# CC2756 register map
File version: 1.0
CPU: CM4 r0p4, little endian, no MPU, no FPU, VTOR, 3 interrupt priority bits
Registers are 32-bit, read-write, reset 0x0 unless marked. A register's access mark holds for its fields unless they carry their own. Offsets are from the block's base; [hi:lo] are bit positions.

## SAU
Base 0xE000EDD0
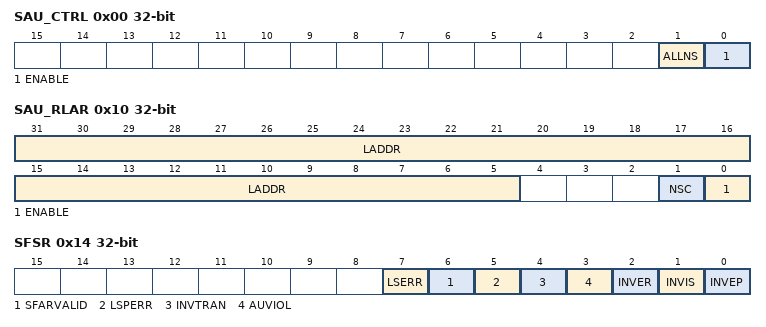
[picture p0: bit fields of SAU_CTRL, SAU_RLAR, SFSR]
0x00 SAU_CTRL — Allows enabling of the Security Attribution Unit
  [1] ALLNS — When SAU_CTRL.ENABLE is 0 this bit controls if the memory is marked as Non-secure or Secure
  [0] ENABLE — Enables the SAU
0x04 SAU_TYPE reset 0x4 — Indicates the number of regions implemented by the Security Attribution Unit
  [7:0] SREGION ro — The number of implemented SAU regions
0x08 SAU_RNR — Selects the region currently accessed by SAU_RBAR and SAU_RLAR
  [7:0] REGION — Indicates the SAU region accessed by SAU_RBAR and SAU_RLAR
0x0C SAU_RBAR — Provides indirect read and write access to the base address of the currently selected SAU region
  [31:5] BADDR — Holds bits [31:5] of the base address for the selected SAU region
0x10 SAU_RLAR — Provides indirect read and write access to the limit address of the currently selected SAU region
  [31:5] LADDR — Holds bits [31:5] of the limit address for the selected SAU region
  [1] NSC — Controls whether Non-secure state is permitted to execute an SG instruction from this region
  [0] ENABLE — SAU region enable
0x14 SFSR — Provides information about any security related faults
  [7] LSERR — Sticky flag indicating that an error occurred during lazy state activation or deactivation
  [6] SFARVALID — This bit is set when the SFAR register contains a valid value. As with similar fields, such as BFSR.BFARVALID and MMFSR.MMARVALID, this bit can be cleared by other exceptions, such as BusFault
  [5] LSPERR — Stick flag indicating that an SAU or IDAU violation occurred during the lazy preservation of floating-point state
  [4] INVTRAN — Sticky flag indicating that an exception was raised due to a branch that was not flagged as being domain crossing causing a transition from Secure to Non-secure memory
  [3] AUVIOL — Sticky flag indicating that an attempt was made to access parts of the address space that are marked as Secure with NS-Req for the transaction set to Non-secure. This bit is not set if the violation occurred during lazy state preservation. See LSPERR
  [2] INVER — This can be caused by EXC_RETURN.DCRS being set to 0 when returning from an exception in the Non-secure state, or by EXC_RETURN.ES being set to 1 when returning from an exception in the Non-secure state
  [1] INVIS — This bit is set if the integrity signature in an exception stack frame is found to be invalid during the unstacking operation
  [0] INVEP — This bit is set if a function call from the Non-secure state or exception targets a non-SG instruction in the Secure state. This bit is also set if the target address is a SG instruction, but there is no matching SAU/IDAU region with the NSC flag set
0x18 SFAR — Shows the address of the memory location that caused a Security violation
  [31:0] ADDRESS — The address of an access that caused a attribution unit violation. This field is only valid when SFSR.SFARVALID is set. This allows the actual flip flops associated with this register to be shared with other fault address registers. If an implementation chooses to share the storage in this way, care must be taken to not leak Secure address information to the Non-secure state. One way of achieving this is to share the SFAR register with the MMFAR_S register, which is not accessible to the Non-secure state

## SRAMCTRL — System SRAM Controller
Base 0x400C5000
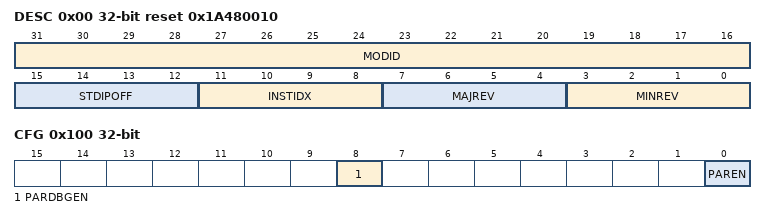
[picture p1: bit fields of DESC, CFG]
0x00 DESC ro reset 0x1A480010 — This register identifies the peripheral
  [31:16] MODID — Module identifier
  [15:12] STDIPOFF — 64 B Standard IP MMR block$lt;br$gt;0: STDIP MMRs do not exist$lt;br$gt;1:15: These MMRs begin at offset 64*STDIPOFF from IP base address
  [11:8] INSTIDX — IP Instance number
  [7:4] MAJREV — Major revision
  [3:0] MINREV — Minor revision
0x64 DTB — This bit field is used to select DTB mux digital inputs
  [1:0] SEL — DTB Selection
0x100 CFG — Configuration Register
  [8] PARDBGEN — SRAM Parity Debug Enable.
    1=EN (Enable Parity Debug. An address offset can be written to PARDBG.ADDR and parity errors will be generated on reads from within this offset); 0=DIS (Disable Parity Debug. Normal operation)
  [0] PAREN — SRAM Parity Enable.
    1=EN (Enable Parity); 0=DIS (Disable Parity)
0x104 INITSEL — Initilizataion Select Register.
  [6:0] SEL — Bank Select. Bit[0]:Bank-0 Bit[1]:Bank-1 ... Bit[n]:Bank-n
0x108 INITTRIG — Initilizataion Select Register. This register is writable only if CFG.LOCKDIS = 1
  [0] TRG — Trigger Initilization. All banks with its INIT.SEL[x] bit set to 1 will be initilizaed. This bit will auto clear once initlization is complete
0x10C INITSTAT ro — Initilizataion Status
  [6:0] BUSY — Each bit indicate that corresponding bank is getting initialzed
0x110 PARDBG — Parity error check debug address setting
  [19:2] ADDR — Debug Parity Error Address Offset.##br##When CFG.PARDBGEN is 1, this field is used to set a parity debug address offset. Writes within this address offset will force incorrect parity bits to be stored together with the data written. The following reads within this same address offset will thus result in parity errors to be generated.
0x114 PARERR ro — Parity error
  [31:0] ADDR — Parity Error Address Offset.##br##This holds the address offset that first generated the parity error and an interrupt is generated. ##br##This register is 'Clear-On-Read'

## SYSTICK
Base 0xE000E010
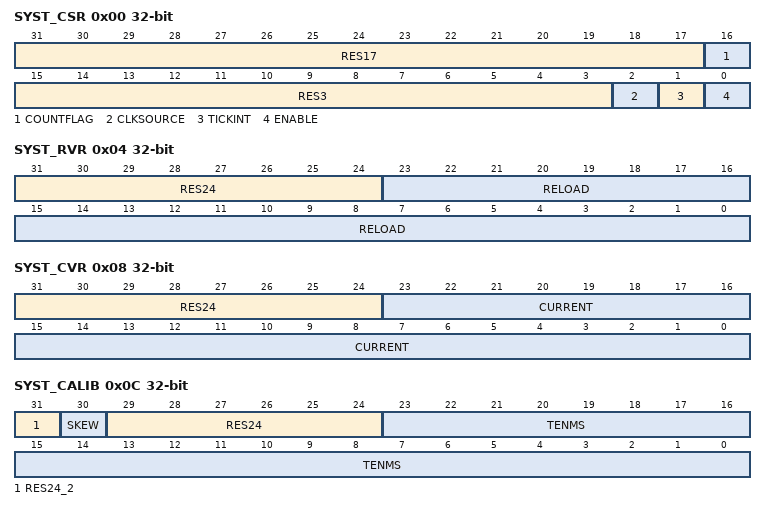
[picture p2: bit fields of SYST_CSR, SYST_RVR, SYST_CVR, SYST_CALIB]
0x00 SYST_CSR — Controls and provides status date for the SysTick timer
  [31:17] RES17 ro — Software should not rely on the value of a reserved. Writing any other value than the reset value may result in undefined behavior.
  [16] COUNTFLAG — Indicates whether the counter has counted to zero since the last read of this register
  [15:3] RES3 ro — Software should not rely on the value of a reserved. Writing any other value than the reset value may result in undefined behavior.
  [2] CLKSOURCE — Indicates the SysTick clock source
  [1] TICKINT — Indicates whether counting to 0 causes the status of the SysTick exception to change to pending
  [0] ENABLE — Indicates the enabled status of the SysTick counter
0x04 SYST_RVR — Specifies the SysTick timer counter reload value
  [31:24] RES24 ro — Software should not rely on the value of a reserved. Writing any other value than the reset value may result in undefined behavior.
  [23:0] RELOAD — Value to load into the SYST_CVR when the counter is enabled and when it reaches 0
0x08 SYST_CVR — Contains the current value of the SysTick counter
  [31:24] RES24 ro — Software should not rely on the value of a reserved. Writing any other value than the reset value may result in undefined behavior.
  [23:0] CURRENT wo — Reads the current value of the SysTick counter. A write of any value clears the field to 0, and also clears the SYST_CSR.COUNTFLAG bit to 0.
0x0C SYST_CALIB — Indicates the SysTick calibration value and parameters for the selected security state
  [31] RES24_2 ro — Software should not rely on the value of a reserved. Writing any other value than the reset value may result in undefined behavior.
  [30] SKEW ro — Indicates whether the TENMS value is exact
  [29:24] RES24 ro — Software should not rely on the value of a reserved. Writing any other value than the reset value may result in undefined behavior.
  [23:0] TENMS ro — Reload value for 10ms (100Hz) timing, subject to system clock skew errors. If the value reads as zero, the calibration value is not known.
